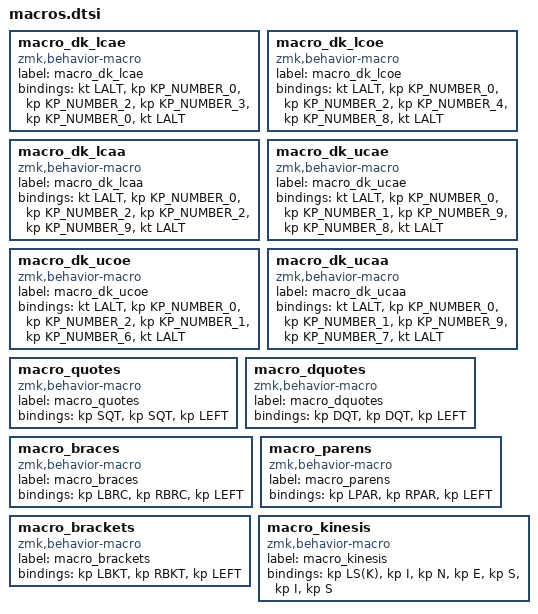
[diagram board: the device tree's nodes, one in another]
macro_dk_lcae: macro_dk_lcae{
compatible = "zmk,behavior-macro";
label = "macro_dk_lcae";
#binding-cells = <0>;
bindings = <&kt LALT>, <&kp KP_NUMBER_0>, <&kp KP_NUMBER_2>, <&kp KP_NUMBER_3>, <&kp KP_NUMBER_0>, <&kt LALT>;
};
macro_dk_lcoe: macro_dk_lcoe{
compatible = "zmk,behavior-macro";
label = "macro_dk_lcoe";
#binding-cells = <0>;
bindings = <&kt LALT>, <&kp KP_NUMBER_0>, <&kp KP_NUMBER_2>, <&kp KP_NUMBER_4>, <&kp KP_NUMBER_8>, <&kt LALT>;
};
macro_dk_lcaa: macro_dk_lcaa{
compatible = "zmk,behavior-macro";
label = "macro_dk_lcaa";
#binding-cells = <0>;
bindings = <&kt LALT>, <&kp KP_NUMBER_0>, <&kp KP_NUMBER_2>, <&kp KP_NUMBER_2>, <&kp KP_NUMBER_9>, <&kt LALT>;
};
macro_dk_ucae: macro_dk_ucae{
compatible = "zmk,behavior-macro";
label = "macro_dk_ucae";
#binding-cells = <0>;
bindings = <&kt LALT>, <&kp KP_NUMBER_0>, <&kp KP_NUMBER_1>, <&kp KP_NUMBER_9>, <&kp KP_NUMBER_8>, <&kt LALT>;
};
macro_dk_ucoe: macro_dk_ucoe{
compatible = "zmk,behavior-macro";
label = "macro_dk_ucoe";
#binding-cells = <0>;
bindings = <&kt LALT>, <&kp KP_NUMBER_0>, <&kp KP_NUMBER_2>, <&kp KP_NUMBER_1>, <&kp KP_NUMBER_6>, <&kt LALT>;
};
macro_dk_ucaa: macro_dk_ucaa{
compatible = "zmk,behavior-macro";
label = "macro_dk_ucaa";
#binding-cells = <0>;
bindings = <&kt LALT>, <&kp KP_NUMBER_0>, <&kp KP_NUMBER_1>, <&kp KP_NUMBER_9>, <&kp KP_NUMBER_7>, <&kt LALT>;
};
macro_quotes: macro_quotes{
compatible = "zmk,behavior-macro";
label = "macro_quotes";
#binding-cells = <0>;
bindings = <&kp SQT>, <&kp SQT>, <&kp LEFT>;
};
macro_dquotes: macro_dquotes{
compatible = "zmk,behavior-macro";
label = "macro_dquotes";
#binding-cells = <0>;
bindings = <&kp DQT>, <&kp DQT>, <&kp LEFT>;
};
macro_braces: macro_braces{
compatible = "zmk,behavior-macro";
label = "macro_braces";
#binding-cells = <0>;
bindings = <&kp LBRC>, <&kp RBRC>, <&kp LEFT>;
};
macro_parens: macro_parens{
compatible = "zmk,behavior-macro";
label = "macro_parens";
#binding-cells = <0>;
bindings = <&kp LPAR>, <&kp RPAR>, <&kp LEFT>;
};
macro_brackets: macro_brackets{
compatible = "zmk,behavior-macro";
label = "macro_brackets";
#binding-cells = <0>;
bindings = <&kp LBKT>, <&kp RBKT>, <&kp LEFT>;
};
macro_kinesis: macro_kinesis{
compatible = "zmk,behavior-macro";
label = "macro_kinesis";
#binding-cells = <0>;
bindings = <&kp LS(K)>, <&kp I>, <&kp N>, <&kp E>, <&kp S>, <&kp I>, <&kp S>;
};
